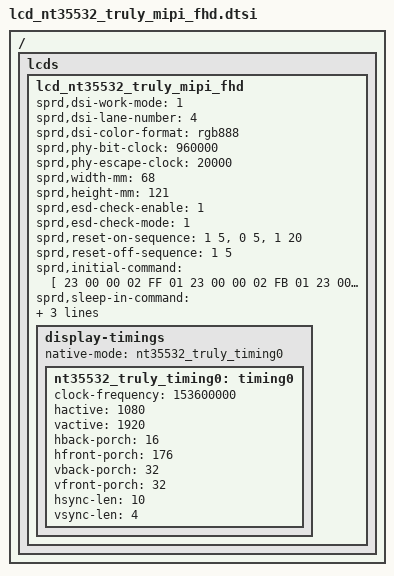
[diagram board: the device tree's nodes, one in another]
// SPDX-License-Identifier: GPL-2.0-only
/*
 * Unisoc NT35696 Truly LCD config DTS file
 *
 * Copyright (C) 2021, Unisoc Inc.
 */
/ {
	fragment {
		target-path = "/";
		__overlay__ {
			lcds {
				lcd_nt35532_truly_mipi_fhd: lcd_nt35532_truly_mipi_fhd {

					sprd,dsi-work-mode = <1>; /* video burst mode*/
					sprd,dsi-lane-number = <4>;
					sprd,dsi-color-format = "rgb888";

					sprd,phy-bit-clock = <960000>;	/* kbps */
					sprd,phy-escape-clock = <20000>;/* kHz */

					sprd,width-mm = <68>;
					sprd,height-mm = <121>;

					sprd,esd-check-enable = <1>;
					sprd,esd-check-mode = <1>;

					sprd,reset-on-sequence = <1 5>, <0 5>, <1 20>;
					sprd,reset-off-sequence = <1 5>;

					sprd,initial-command = [
						23 00 00 02 FF 01
						23 00 00 02 FB 01

						23 00 00 02 00 01
						23 00 00 02 01 44
						23 00 00 02 02 59
						23 00 00 02 04 0C
						23 00 00 02 05 2B
						23 00 00 02 06 64
						23 00 00 02 07 C6
						/*GVDDP 4.3V */
						23 00 00 02 0D 89
						23 00 00 02 0E 89

						23 00 00 02 0F E0
						23 00 00 02 10 03
						23 00 00 02 11 5A
						23 00 00 02 12 5A
						//vcom
						23 00 00 02 13 7e
						23 00 00 02 14 7e
						23 00 00 02 15 60

						23 00 00 02 16 13
						23 00 00 02 17 13
						23 00 00 02 1C A3
						23 00 00 02 6E 80
						23 00 00 02 60 77
						23 00 00 02 68 13

						/*gamma */
						/*R(+) MCR cmd */
						23 00 00 02 75 00
						23 00 00 02 76 77
						23 00 00 02 77 00
						23 00 00 02 78 78
						23 00 00 02 79 00
						23 00 00 02 7A B0
						23 00 00 02 7B 00
						23 00 00 02 7C CC
						23 00 00 02 7D 00
						23 00 00 02 7E E3
						23 00 00 02 7F 00
						23 00 00 02 80 F6
						23 00 00 02 81 01
						23 00 00 02 82 06
						23 00 00 02 83 01
						23 00 00 02 84 15
						23 00 00 02 85 01
						23 00 00 02 86 22
						23 00 00 02 87 01
						23 00 00 02 88 4E
						23 00 00 02 89 01
						23 00 00 02 8A 71
						23 00 00 02 8B 01
						23 00 00 02 8C A7
						23 00 00 02 8D 01
						23 00 00 02 8E D2
						23 00 00 02 8F 02
						23 00 00 02 90 14
						23 00 00 02 91 02
						23 00 00 02 92 49
						23 00 00 02 93 02
						23 00 00 02 94 4B
						23 00 00 02 95 02
						23 00 00 02 96 7D
						23 00 00 02 97 02
						23 00 00 02 98 B6
						23 00 00 02 99 02
						23 00 00 02 9A D9
						23 00 00 02 9B 03
						23 00 00 02 9C 0D
						23 00 00 02 9D 03
						23 00 00 02 9E 2A
						23 00 00 02 9F 03
						23 00 00 02 A0 51
						23 00 00 02 A2 03
						23 00 00 02 A3 5D
						23 00 00 02 A4 03
						23 00 00 02 A5 6A
						23 00 00 02 A6 03
						23 00 00 02 A7 78
						23 00 00 02 A9 03
						23 00 00 02 AA 89
						23 00 00 02 AB 03
						23 00 00 02 AC 9E
						23 00 00 02 AD 03
						23 00 00 02 AE B7
						23 00 00 02 AF 03
						23 00 00 02 B0 CE
						23 00 00 02 B1 03
						23 00 00 02 B2 D1
						/*R(-) MCR cmd */
						23 00 00 02 B3 00
						23 00 00 02 B4 18
						23 00 00 02 B5 00
						23 00 00 02 B6 6A
						23 00 00 02 B7 00
						23 00 00 02 B8 B0
						23 00 00 02 B9 00
						23 00 00 02 BA CC
						23 00 00 02 BB 00
						23 00 00 02 BC E3
						23 00 00 02 BD 00
						23 00 00 02 BE F6
						23 00 00 02 BF 01
						23 00 00 02 C0 06
						23 00 00 02 C1 01
						23 00 00 02 C2 15
						23 00 00 02 C3 01
						23 00 00 02 C4 22
						23 00 00 02 C5 01
						23 00 00 02 C6 4E
						23 00 00 02 C7 01
						23 00 00 02 C8 71
						23 00 00 02 C9 01
						23 00 00 02 CA A7
						23 00 00 02 CB 01
						23 00 00 02 CC D2
						23 00 00 02 CD 02
						23 00 00 02 CE 14
						23 00 00 02 CF 02
						23 00 00 02 D0 49
						23 00 00 02 D1 02
						23 00 00 02 D2 4B
						23 00 00 02 D3 02
						23 00 00 02 D4 7D
						23 00 00 02 D5 02
						23 00 00 02 D6 B6
						23 00 00 02 D7 02
						23 00 00 02 D8 D9
						23 00 00 02 D9 03
						23 00 00 02 DA 0D
						23 00 00 02 DB 03
						23 00 00 02 DC 2A
						23 00 00 02 DD 03
						23 00 00 02 DE 51
						23 00 00 02 DF 03
						23 00 00 02 E0 5D
						23 00 00 02 E1 03
						23 00 00 02 E2 6A
						23 00 00 02 E3 03
						23 00 00 02 E4 78
						23 00 00 02 E5 03
						23 00 00 02 E6 89
						23 00 00 02 E7 03
						23 00 00 02 E8 9E
						23 00 00 02 E9 03
						23 00 00 02 EA B7
						23 00 00 02 EB 03
						23 00 00 02 EC CE
						23 00 00 02 ED 03
						23 00 00 02 EE D1
						/*G(+) MCR cmd */
						23 00 00 02 EF 00
						23 00 00 02 F0 77
						23 00 00 02 F1 00
						23 00 00 02 F2 78
						23 00 00 02 F3 00
						23 00 00 02 F4 B0
						23 00 00 02 F5 00
						23 00 00 02 F6 CC
						23 00 00 02 F7 00
						23 00 00 02 F8 E3
						23 00 00 02 F9 00
						23 00 00 02 FA F6
						/*page selection cmd start */
						23 00 00 02 FF 02
						23 00 00 02 FB 01
						/*page selection cmd end */
						23 00 00 02 00 01
						23 00 00 02 01 06
						23 00 00 02 02 01
						23 00 00 02 03 15
						23 00 00 02 04 01
						23 00 00 02 05 22
						23 00 00 02 06 01
						23 00 00 02 07 4E
						23 00 00 02 08 01
						23 00 00 02 09 71
						23 00 00 02 0A 01
						23 00 00 02 0B A7
						23 00 00 02 0C 01
						23 00 00 02 0D D2
						23 00 00 02 0E 02
						23 00 00 02 0F 14
						23 00 00 02 10 02
						23 00 00 02 11 49
						23 00 00 02 12 02
						23 00 00 02 13 4B
						23 00 00 02 14 02
						23 00 00 02 15 7D
						23 00 00 02 16 02
						23 00 00 02 17 B6
						23 00 00 02 18 02
						23 00 00 02 19 D9
						23 00 00 02 1A 03
						23 00 00 02 1B 0D
						23 00 00 02 1C 03
						23 00 00 02 1D 2A
						23 00 00 02 1E 03
						23 00 00 02 1F 51
						23 00 00 02 20 03
						23 00 00 02 21 5D
						23 00 00 02 22 03
						23 00 00 02 23 6A
						23 00 00 02 24 03
						23 00 00 02 25 78
						23 00 00 02 26 03
						23 00 00 02 27 89
						23 00 00 02 28 03
						23 00 00 02 29 9E
						23 00 00 02 2A 03
						23 00 00 02 2B B7
						23 00 00 02 2D 03
						23 00 00 02 2F CE
						23 00 00 02 30 03
						23 00 00 02 31 D1
						/*G(-) MCR cmd */
						23 00 00 02 32 00
						23 00 00 02 33 18
						23 00 00 02 34 00
						23 00 00 02 35 6A
						23 00 00 02 36 00
						23 00 00 02 37 B0
						23 00 00 02 38 00
						23 00 00 02 39 CC
						23 00 00 02 3A 00
						23 00 00 02 3B E3
						23 00 00 02 3D 00
						23 00 00 02 3F F6
						23 00 00 02 40 01
						23 00 00 02 41 06
						23 00 00 02 42 01
						23 00 00 02 43 15
						23 00 00 02 44 01
						23 00 00 02 45 22
						23 00 00 02 46 01
						23 00 00 02 47 4E
						23 00 00 02 48 01
						23 00 00 02 49 71
						23 00 00 02 4A 01
						23 00 00 02 4B A7
						23 00 00 02 4C 01
						23 00 00 02 4D D2
						23 00 00 02 4E 02
						23 00 00 02 4F 14
						23 00 00 02 50 02
						23 00 00 02 51 49
						23 00 00 02 52 02
						23 00 00 02 53 4B
						23 00 00 02 54 02
						23 00 00 02 55 7D
						23 00 00 02 56 02
						23 00 00 02 58 B6
						23 00 00 02 59 02
						23 00 00 02 5A D9
						23 00 00 02 5B 03
						23 00 00 02 5C 0D
						23 00 00 02 5D 03
						23 00 00 02 5E 2A
						23 00 00 02 5F 03
						23 00 00 02 60 51
						23 00 00 02 61 03
						23 00 00 02 62 5D
						23 00 00 02 63 03
						23 00 00 02 64 6A
						23 00 00 02 65 03
						23 00 00 02 66 78
						23 00 00 02 67 03
						23 00 00 02 68 89
						23 00 00 02 69 03
						23 00 00 02 6A 9E
						23 00 00 02 6B 03
						23 00 00 02 6C B7
						23 00 00 02 6D 03
						23 00 00 02 6E CE
						23 00 00 02 6F 03
						23 00 00 02 70 D1
						/*B(+) MCR cmd */
						23 00 00 02 71 00
						23 00 00 02 72 77
						23 00 00 02 73 00
						23 00 00 02 74 78
						23 00 00 02 75 00
						23 00 00 02 76 B0
						23 00 00 02 77 00
						23 00 00 02 78 CC
						23 00 00 02 79 00
						23 00 00 02 7A E3
						23 00 00 02 7B 00
						23 00 00 02 7C F6
						23 00 00 02 7D 01
						23 00 00 02 7E 06
						23 00 00 02 7F 01
						23 00 00 02 80 15
						23 00 00 02 81 01
						23 00 00 02 82 22
						23 00 00 02 83 01
						23 00 00 02 84 4E
						23 00 00 02 85 01
						23 00 00 02 86 71
						23 00 00 02 87 01
						23 00 00 02 88 A7
						23 00 00 02 89 01
						23 00 00 02 8A D2
						23 00 00 02 8B 02
						23 00 00 02 8C 14
						23 00 00 02 8D 02
						23 00 00 02 8E 49
						23 00 00 02 8F 02
						23 00 00 02 90 4B
						23 00 00 02 91 02
						23 00 00 02 92 7D
						23 00 00 02 93 02
						23 00 00 02 94 B6
						23 00 00 02 95 02
						23 00 00 02 96 D9
						23 00 00 02 97 03
						23 00 00 02 98 0D
						23 00 00 02 99 03
						23 00 00 02 9A 2A
						23 00 00 02 9B 03
						23 00 00 02 9C 51
						23 00 00 02 9D 03
						23 00 00 02 9E 5D
						23 00 00 02 9F 03
						23 00 00 02 A0 6A
						23 00 00 02 A2 03
						23 00 00 02 A3 78
						23 00 00 02 A4 03
						23 00 00 02 A5 89
						23 00 00 02 A6 03
						23 00 00 02 A7 9E
						23 00 00 02 A9 03
						23 00 00 02 AA B7
						23 00 00 02 AB 03
						23 00 00 02 AC CE
						23 00 00 02 AD 03
						23 00 00 02 AE D1
						/*B(-) MCR cmd */
						23 00 00 02 AF 00
						23 00 00 02 B0 18
						23 00 00 02 B1 00
						23 00 00 02 B2 6A
						23 00 00 02 B3 00
						23 00 00 02 B4 B0
						23 00 00 02 B5 00
						23 00 00 02 B6 CC
						23 00 00 02 B7 00
						23 00 00 02 B8 E3
						23 00 00 02 B9 00
						23 00 00 02 BA F6
						23 00 00 02 BB 01
						23 00 00 02 BC 06
						23 00 00 02 BD 01
						23 00 00 02 BE 15
						23 00 00 02 BF 01
						23 00 00 02 C0 22
						23 00 00 02 C1 01
						23 00 00 02 C2 4E
						23 00 00 02 C3 01
						23 00 00 02 C4 71
						23 00 00 02 C5 01
						23 00 00 02 C6 A7
						23 00 00 02 C7 01
						23 00 00 02 C8 D2
						23 00 00 02 C9 02
						23 00 00 02 CA 14
						23 00 00 02 CB 02
						23 00 00 02 CC 49
						23 00 00 02 CD 02
						23 00 00 02 CE 4B
						23 00 00 02 CF 02
						23 00 00 02 D0 7D
						23 00 00 02 D1 02
						23 00 00 02 D2 B6
						23 00 00 02 D3 02
						23 00 00 02 D4 D9
						23 00 00 02 D5 03
						23 00 00 02 D6 0D
						23 00 00 02 D7 03
						23 00 00 02 D8 2A
						23 00 00 02 D9 03
						23 00 00 02 DA 51
						23 00 00 02 DB 03
						23 00 00 02 DC 5D
						23 00 00 02 DD 03
						23 00 00 02 DE 6A
						23 00 00 02 DF 03
						23 00 00 02 E0 78
						23 00 00 02 E1 03
						23 00 00 02 E2 89
						23 00 00 02 E3 03
						23 00 00 02 E4 9E
						23 00 00 02 E5 03
						23 00 00 02 E6 B7
						23 00 00 02 E7 03
						23 00 00 02 E8 CE
						23 00 00 02 E9 03
						23 00 00 02 EA D1


						23 00 00 02 FF 05
						23 00 00 02 FB 01

						23 00 00 02 00 38
						23 00 00 02 01 38
						23 00 00 02 02 07
						23 00 00 02 03 40
						23 00 00 02 04 40
						23 00 00 02 05 25
						23 00 00 02 06 1D
						23 00 00 02 07 23
						23 00 00 02 08 1B
						23 00 00 02 09 21
						23 00 00 02 0A 19
						23 00 00 02 0B 1F
						23 00 00 02 0C 17
						23 00 00 02 0D 05
						23 00 00 02 0E 04
						23 00 00 02 0F 0F
						23 00 00 02 10 38
						23 00 00 02 11 38
						23 00 00 02 12 38
						23 00 00 02 13 38
						23 00 00 02 14 38
						23 00 00 02 15 38
						23 00 00 02 16 06
						23 00 00 02 17 40
						23 00 00 02 18 40
						23 00 00 02 19 24
						23 00 00 02 1A 1C
						23 00 00 02 1B 22
						23 00 00 02 1C 1A
						23 00 00 02 1D 20
						23 00 00 02 1E 18
						23 00 00 02 1F 1E
						23 00 00 02 20 16
						23 00 00 02 21 05
						23 00 00 02 22 04
						23 00 00 02 23 0E
						23 00 00 02 24 38
						23 00 00 02 25 38
						23 00 00 02 26 38
						23 00 00 02 27 38
						23 00 00 02 28 38
						23 00 00 02 29 38
						23 00 00 02 2A 0E
						23 00 00 02 2B 40
						23 00 00 02 2D 40
						23 00 00 02 2F 16
						23 00 00 02 30 1E
						23 00 00 02 31 18
						23 00 00 02 32 20
						23 00 00 02 33 1A
						23 00 00 02 34 22
						23 00 00 02 35 1C
						23 00 00 02 36 24
						23 00 00 02 37 05
						23 00 00 02 38 04
						23 00 00 02 39 06
						23 00 00 02 3A 38
						23 00 00 02 3B 38
						23 00 00 02 3D 38
						23 00 00 02 3F 38
						23 00 00 02 40 38
						23 00 00 02 41 38
						23 00 00 02 42 0F
						23 00 00 02 43 40
						23 00 00 02 44 40
						23 00 00 02 45 17
						23 00 00 02 46 1F
						23 00 00 02 47 19
						23 00 00 02 48 21
						23 00 00 02 49 1B
						23 00 00 02 4A 23
						23 00 00 02 4B 1D
						23 00 00 02 4C 25
						23 00 00 02 4D 05
						23 00 00 02 4E 04
						23 00 00 02 4F 07
						23 00 00 02 50 38
						23 00 00 02 51 38
						23 00 00 02 52 38
						23 00 00 02 53 38
						23 00 00 02 5B 0A
						23 00 00 02 5C 0A
						23 00 00 02 63 0A
						23 00 00 02 64 15
						23 00 00 02 68 24
						23 00 00 02 69 24
						23 00 00 02 90 7B
						23 00 00 02 91 10  /*VFP */
						23 00 00 02 92 15  /*VBP */
						23 00 00 02 7E 10
						23 00 00 02 7F 10
						23 00 00 02 80 00
						23 00 00 02 98 00
						23 00 00 02 99 00
						23 00 00 02 54 2E
						23 00 00 02 59 38
						23 00 00 02 5D 01
						23 00 00 02 5E 27
						23 00 00 02 62 39
						23 00 00 02 66 88
						23 00 00 02 67 11
						23 00 00 02 6A 0E
						23 00 00 02 6B 20
						23 00 00 02 6C 08
						23 00 00 02 6D 00
						23 00 00 02 7D 01
						23 00 00 02 B7 01
						23 00 00 02 B8 0A
						23 00 00 02 BA 13
						23 00 00 02 BC 01
						23 00 00 02 BD 55
						23 00 00 02 BE 38
						23 00 00 02 BF 44
						23 00 00 02 CF 88
						23 00 00 02 C8 00
						23 00 00 02 C9 55
						23 00 00 02 CA 00
						23 00 00 02 CB 55
						23 00 00 02 CC A2
						23 00 00 02 CE 88
						23 00 00 02 CF 88
						23 00 00 02 D0 00
						23 00 00 02 D1 00
						23 00 00 02 D3 00
						23 00 00 02 D5 00
						23 00 00 02 D6 22
						23 00 00 02 D7 31
						23 00 00 02 D8 7E

						23 00 00 02 FF 00   /*CMD1 */
						23 00 00 02 FB 01
						23 00 00 02 D3 24   /*VBP */
						23 00 00 02 D4 20   /*VFP */
						23 00 00 02 D5 5A   /*HBP */
						23 00 00 02 D6 50   /*HFP */
						23 00 00 02 D7 00
						23 00 00 02 35 00

						23 00 00 02 FF 00
						23 00 00 02 FB 01
						23 00 00 02 51 FF
						23 00 00 02 53 2C
						23 00 00 02 36 00
						13 78 00 01 11
						13 0a 00 01 29

						];
					sprd,sleep-in-command = [
						13 01 00 01 00
						13 0A 00 01 28
						13 78 00 01 10
						23 0a 00 02 4F 01
						];
					sprd,sleep-out-command = [
						13 78 00 01 11
						13 32 00 01 29
						];

					display-timings {
						native-mode = <&nt35532_truly_timing0>;

						nt35532_truly_timing0: timing0 {
							clock-frequency = <153600000>;
							hactive = <1080>;
							vactive = <1920>;
							hback-porch = <16>;
							hfront-porch = <176>;
							vback-porch = <32>;
							vfront-porch = <32>;
							hsync-len = <10>;
							vsync-len = <4>;
						};
					};
				};
			};
		};
	};
};
